# BlueNRG_LPF register map
File version: 1.0
CPU: CM0+ r0p0, little endian, no MPU, no FPU, 2 interrupt priority bits
Registers are 32-bit, read-write, reset 0x0 unless marked. A register's access mark holds for its fields unless they carry their own. Offsets are from the block's base; [hi:lo] are bit positions; {n}, {i} and the like mark numbered series.

## USART1 — Universal synchronous asynchronous receiver transmitter
Base 0x41004000
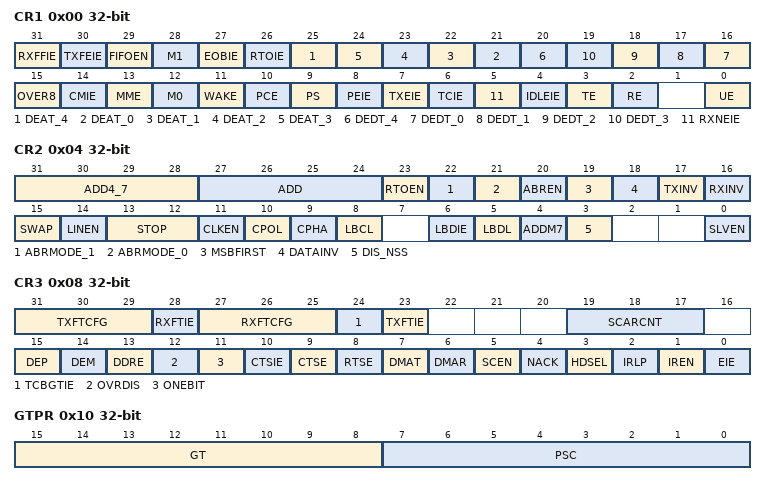
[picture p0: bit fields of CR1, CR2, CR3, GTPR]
0x00 CR1 — Control register 1
  [31] RXFFIE
  [30] TXFEIE
  [29] FIFOEN
  [28] M1 — Word length
  [27] EOBIE — End of Block interrupt enable
  [26] RTOIE — Receiver timeout interrupt enable
  [25] DEAT_4 — Driver Enable assertion time
  [n+21] DEAT_{n} (n=0..3)
  [20] DEDT_4 — Driver Enable de-assertion time
  [n+16] DEDT_{n} (n=0..3)
  [15] OVER8 — Oversampling mode
  [14] CMIE — Character match interrupt enable
  [13] MME — Mute mode enable
  [12] M0 — Word length
  [11] WAKE — Receiver wakeup method
  [10] PCE — Parity control enable
  [9] PS — Parity selection
  [8] PEIE — PE interrupt enable
  [7] TXEIE — interrupt enable
  [6] TCIE — Transmission complete interrupt enable
  [5] RXNEIE — RXNE interrupt enable
  [4] IDLEIE — IDLE interrupt enable
  [3] TE — Transmitter enable
  [2] RE — Receiver enable
  [0] UE — USART enable
0x04 CR2 — Control register 2
  [31:28] ADD4_7 — Address of the USART node
  [27:24] ADD — Address of the USART node
  [23] RTOEN — Receiver timeout enable
  [22] ABRMODE_1 — Auto baud rate mode
  [21] ABRMODE_0 — ABRMOD0
  [20] ABREN — Auto baud rate enable
  [19] MSBFIRST — Most significant bit first
  [18] DATAINV — Binary data inversion
  [17] TXINV — TX pin active level inversion
  [16] RXINV — RX pin active level inversion
  [15] SWAP — Swap TX/RX pins
  [14] LINEN — LIN mode enable
  [13:12] STOP — STOP bits
  [11] CLKEN
  [10] CPOL — Clock polarity
  [9] CPHA — Clock phase
  [8] LBCL — Last bit clock pulse
  [6] LBDIE — LIN break detection interrupt enable
  [5] LBDL — LIN break detection length
  [4] ADDM7 — 7-bit Address Detection/4-bit address Detection
  [3] DIS_NSS
  [0] SLVEN
0x08 CR3 — Control register 3
  [31:29] TXFTCFG — TXFIFO threshold configuration
  [28] RXFTIE
  [27:25] RXFTCFG — Receive FIFO threshold configuration
  [24] TCBGTIE — Transmission Complete before guard time, interrupt enable
  [23] TXFTIE — TXFIFO threshold interrupt enable
  [19:17] SCARCNT — Smartcard auto-retry count
  [15] DEP — Driver enable polarity selection
  [14] DEM — Driver enable mode
  [13] DDRE — DMA Disable on Reception Error
  [12] OVRDIS — Overrun Disable
  [11] ONEBIT — One sample bit method enable
  [10] CTSIE — CTs interrupt enable
  [9] CTSE — CTs enable
  [8] RTSE — RTs enable
  [7] DMAT — DMA enable transmitter
  [6] DMAR — DMA enable receiver
  [5] SCEN — Smartcard mode enable
  [4] NACK — Smartcard NACK enable
  [3] HDSEL — Half-duplex selection
  [2] IRLP — IrDA low-power
  [1] IREN — IrDA mode enable
  [0] EIE — Error interrupt enable
0x0C BRR — Baud rate register
  [15:0] BRR
0x10 GTPR — Guard time and prescaler register
  [15:8] GT — Guard time value
  [7:0] PSC — Prescaler value
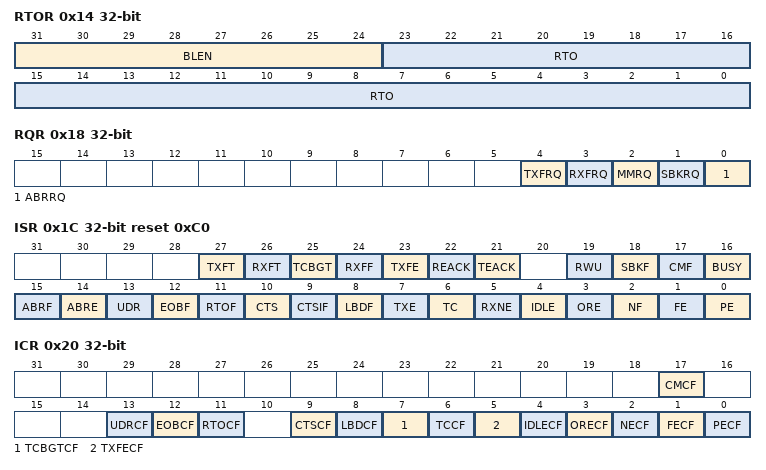
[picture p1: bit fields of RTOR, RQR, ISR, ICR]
0x14 RTOR — Receiver timeout register
  [31:24] BLEN — Block Length
  [23:0] RTO — Receiver timeout value
0x18 RQR — Request register
  [4] TXFRQ — Transmit data flush request
  [3] RXFRQ — Receive data flush request
  [2] MMRQ — Mute mode request
  [1] SBKRQ — Send break request
  [0] ABRRQ — Auto baud rate request
0x1C ISR ro reset 0xC0 — Interrupt and status register
  [27] TXFT — TXFIFO threshold flag
  [26] RXFT — RXFIFO threshold flag
  [25] TCBGT — Transmission complete before guard time flagl
  [24] RXFF — RXFIFO Full
  [23] TXFE — TXFIFO Empty
  [22] REACK — Receive enable acknowledge flag
  [21] TEACK — Transmit enable acknowledge flag
  [19] RWU — Receiver wakeup from Mute mode
  [18] SBKF — Send break flag
  [17] CMF — Character match flag
  [16] BUSY — Busy flag
  [15] ABRF — Auto baud rate flag
  [14] ABRE — Auto baud rate error
  [13] UDR — SPI slave underrun error flag
  [12] EOBF — End of block flag
  [11] RTOF — Receiver timeout
  [10] CTS — CTs flag
  [9] CTSIF — CTs interrupt flag
  [8] LBDF — LIN break detection flag
  [7] TXE — Transmit data register empty/TXFIFO not full
  [6] TC — Transmission complete
  [5] RXNE — data register not empty/RXFIFO not empty
  [4] IDLE — Idle line detected
  [3] ORE — Overrun error
  [2] NF — START bit Noise error detection flag
  [1] FE — Framing error
  [0] PE — Parity error
0x20 ICR wo — Interrupt flag clear register
  [17] CMCF — Character match clear flag
  [13] UDRCF — slave underrun clear flag
  [12] EOBCF — End of block clear flag
  [11] RTOCF — Receiver timeout clear flag
  [9] CTSCF — CTs clear flag
  [8] LBDCF — LIN break detection clear flag
  [7] TCBGTCF — Transmission complete before Guard time clear flag
  [6] TCCF — Transmission complete clear flag
  [5] TXFECF — TXFIFO empty clear flag
  [4] IDLECF — Idle line detected clear flag
  [3] ORECF — Overrun error clear flag
  [2] NECF — Noise error detected clear flag
  [1] FECF — Framing error clear flag
  [0] PECF — Parity error clear flag
0x24 RDR ro — Receive data register
  [8:0] RDR — Receive data value
0x28 TDR — Transmit data register
  [8:0] TDR — Transmit data value
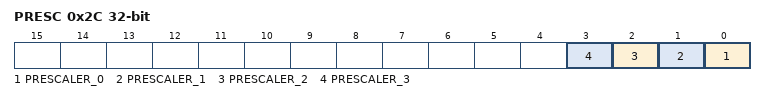
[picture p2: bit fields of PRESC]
0x2C PRESC — Prescaler register
  [n] PRESCALER_{n} (n=0..3)
